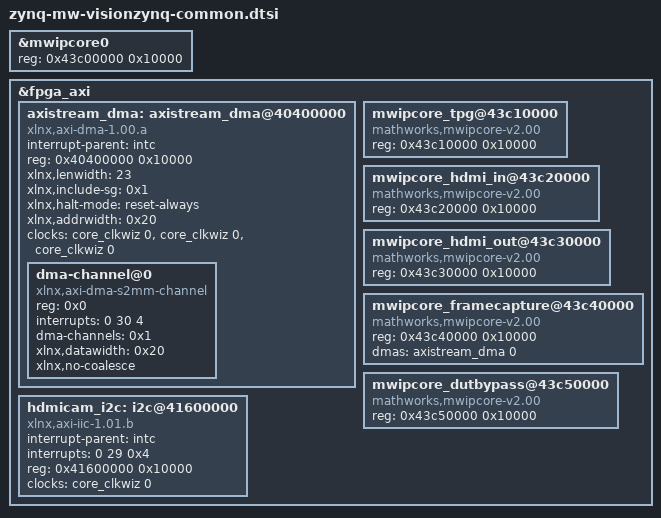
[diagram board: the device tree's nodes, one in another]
#include "zynq-mw-cma.dtsi"

&mwipcore0 {
	reg = <0x43c00000 0x10000>;
};

&fpga_axi {
				
	axistream_dma: axistream_dma@40400000 {
		#dma-cells = <0x1>;
		#address-cells = <0x1>;
		#size-cells = <0x0>;
		compatible = "xlnx,axi-dma-1.00.a";
		interrupt-parent = <&intc>;
		reg = <0x40400000 0x10000>;
		xlnx,lenwidth = <23>;
		xlnx,include-sg = <0x1>;
		xlnx,halt-mode = "reset-always";
		xlnx,addrwidth = <0x20>;
		clocks = <&core_clkwiz 0>, <&core_clkwiz 0>, <&core_clkwiz 0>;
		clock-names = "s_axi_lite_aclk", "m_axi_sg_aclk", "m_axi_s2mm_aclk";

		dma-channel@0 {
			reg = <0x0>;
			compatible = "xlnx,axi-dma-s2mm-channel";
			interrupts = <0 30 4>;
			dma-channels = <0x1>;
			xlnx,datawidth = <0x20>;
			xlnx,no-coalesce;
		};
	};

	mwipcore_tpg@43c10000 {
		compatible = "mathworks,mwipcore-v2.00";
		reg = <0x43c10000 0x10000>;
	};

	mwipcore_hdmi_in@43c20000 {
		compatible = "mathworks,mwipcore-v2.00";
		reg = <0x43c20000 0x10000>;
	};

	mwipcore_hdmi_out@43c30000 {
		compatible = "mathworks,mwipcore-v2.00";
		reg = <0x43c30000 0x10000>;
	};

	mwipcore_framecapture@43c40000 {
		compatible = "mathworks,mwipcore-v2.00";
		reg = <0x43c40000 0x10000>;
		dmas = <&axistream_dma 0>; 
		dma-names = "s2mm";
	};

	mwipcore_dutbypass@43c50000 {
		compatible = "mathworks,mwipcore-v2.00";
		reg = <0x43c50000 0x10000>;
	};


	hdmicam_i2c: i2c@41600000 {
		compatible = "xlnx,axi-iic-1.01.b", "xlnx,xps-iic-2.00.a";
		interrupt-parent = <&intc>;
		interrupts = <0 29 0x4>;
		reg = <0x41600000 0x10000>;
		clocks = <&core_clkwiz 0>;
		clock-names = "pclk";

		#size-cells = <0>;
		#address-cells = <1>;
	};
};

#include "zynq-mw-hdmicam-common.dtsi"

